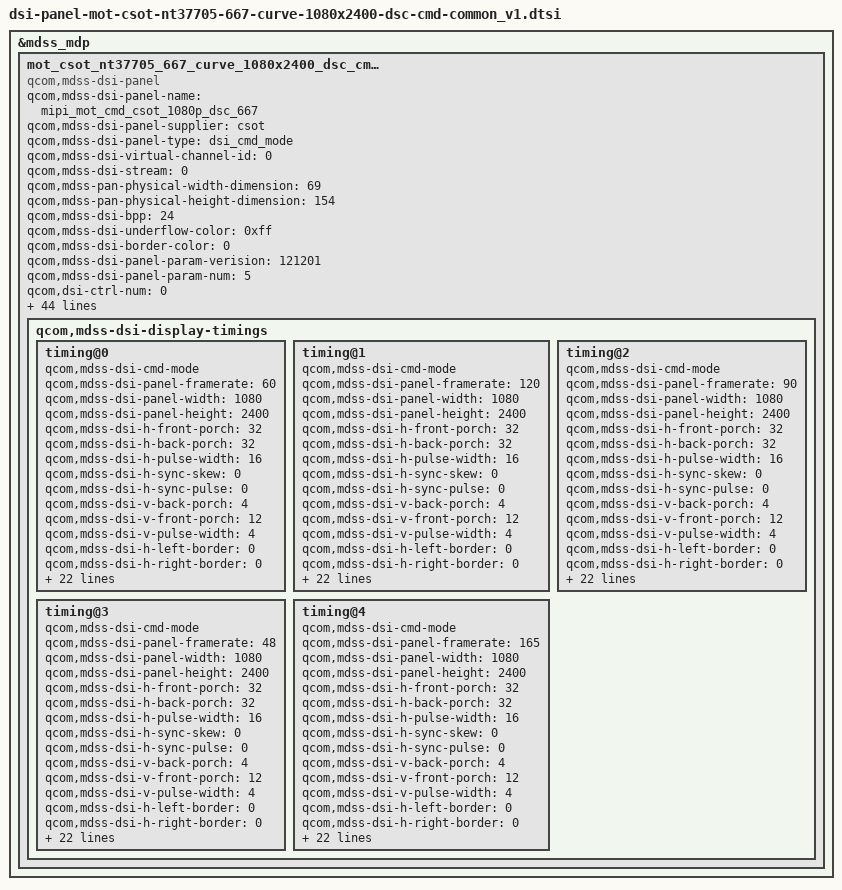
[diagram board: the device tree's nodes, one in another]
/* Copyright (c) 2019-2020, The Linux Foundation. All rights reserved.
 *
 * This program is free software; you can redistribute it and/or modify
 * it under the terms of the GNU General Public License version 2 and
 * only version 2 as published by the Free Software Foundation.
 *
 * This program is distributed in the hope that it will be useful,
 * but WITHOUT ANY WARRANTY; without even the implied warranty of
 * MERCHANTABILITY or FITNESS FOR A PARTICULAR PURPOSE.  See the
 * GNU General Public License for more details.
 */
#include "dsi-panel-mot-csot-nt37705-667-curve-1080x2400-dsc-cmd-common_v1_lhbm.dtsi"
&mdss_mdp {
mot_csot_nt37705_667_curve_1080x2400_dsc_cmd_v1: qcom,mdss_dsi_mot_csot_nt37705_667_curve_1080x2400_dsc_cmd_v1 {
compatible = "qcom,mdss-dsi-panel";
qcom,mdss-dsi-panel-name = "mipi_mot_cmd_csot_1080p_dsc_667";
qcom,mdss-dsi-panel-supplier = "csot";
qcom,mdss-dsi-panel-type = "dsi_cmd_mode";
qcom,mdss-dsi-virtual-channel-id = <0>;
qcom,mdss-dsi-stream = <0>;
qcom,mdss-pan-physical-width-dimension = <69>;
qcom,mdss-pan-physical-height-dimension = <154>;
qcom,mdss-dsi-bpp = <24>;
qcom,mdss-dsi-underflow-color = <0xff>;
qcom,mdss-dsi-border-color = <0>;
qcom,mdss-dsi-panel-param-verision = <121201>;
qcom,mdss-dsi-panel-param-num = <5>;

qcom,dsi-ctrl-num = <0>;
qcom,dsi-phy-num = <0>;

qcom,mdss-dsi-traffic-mode = "burst_mode";
qcom,mdss-dsi-bllp-eof-power-mode;
qcom,mdss-dsi-bllp-power-mode;
qcom,mdss-dsi-lane-0-state;
qcom,mdss-dsi-lane-1-state;
qcom,mdss-dsi-lane-2-state;
qcom,mdss-dsi-lane-3-state;

qcom,mdss-dsi-dma-trigger = "trigger_sw";
qcom,mdss-dsi-mdp-trigger = "none";
qcom,mdss-dsi-reset-sequence = <0 12>, <1 1>, <0 1>, <1 13>;
qcom,mdss-dsi-lp11-init;
qcom,mdss-dsi-tx-eot-append;
qcom,mdss-dsi-te-pin-select = <1>;
qcom,mdss-dsi-te-dcs-command = <1>;
qcom,mdss-dsi-te-using-te-pin;

//qcom,bklt-dcs-2bytes-enabled;
qcom,mdss-dsi-bl-min-level = <4>;
qcom,mdss-dsi-bl-max-level = <14056>;
qcom,mdss-dsi-bl-pmic-control-type = "bl_ctrl_dcs";

qcom,mdss-dsi-panel-hdr-enabled;
qcom,mdss-dsi-panel-hdr-color-primaries = <14500 15500 32000
	        17000 15500 30000 8000 3000>;
qcom,mdss-dsi-panel-peak-brightness = <4200000>;

qcom,mdss-dsi-panel-blackness-level = <3230>;

qcom,mdss-dsi-dc-on-command = [
		39 00 00 00 00 00 06 F0 55 AA 52 08 00
		39 00 00 40 00 00 02 B2 81
		39 00 00 40 00 00 02 6F 02
		39 00 00 40 00 00 02 B2 3F
		39 00 00 40 00 00 02 6F 11
		39 00 00 00 00 00 04 B2 00 00 00
		39 00 00 40 00 00 1F B3 00 00 00 00 00 00 00 00 00 00 00 00 00 00 00 00 00 00 00 00 00 00 00 00 00 00 00 00 06 8F
		39 00 00 40 00 00 02 6F 1E
		39 00 00 00 00 00 0F B3 06 90 06 90 09 08 09 08 0D BA 0D BA 0F FF
		39 00 00 40 00 00 06 F0 55 AA 52 08 00
		39 00 00 40 00 00 02 6F 2E
		39 00 00 40 00 00 04 C0 08 9A BC
		39 00 00 40 00 00 06 F0 55 AA 52 08 02
		39 00 00 00 00 00 02 CC 10
		];

qcom,mdss-dsi-dc-on-command-state = "dsi_hs_mode";
qcom,mdss-dsi-dc-off-command = [
		39 00 00 00 00 00 06 F0 55 AA 52 08 00
		39 00 00 40 00 00 02 B2 01
		39 00 00 40 00 00 1F B3 00 01 01 59 01 59 02 1A 02 1A 03 0A 03 0A 04 44 04 44 05 8E 05 8E 06 8A 06 8A 06 8F 06 8F
		39 00 00 40 00 00 02 6F 1E
		39 00 00 00 00 00 0F B3 06 90 06 90 09 08 09 08 0D BA 0D BA 0F FF
		39 00 00 40 00 00 06 F0 55 AA 52 08 00
                39 00 00 40 00 00 02 6F 11
		39 00 00 00 00 00 04 B2 0B 05 44
		39 00 00 40 00 00 02 6F 2E
		39 00 00 00 00 00 04 C0 12 34 56
		39 00 00 40 00 00 06 F0 55 AA 52 08 02
		39 00 00 00 00 00 02 CC 10
		];
qcom,mdss-dsi-dc-off-command-state = "dsi_hs_mode";

qcom,mdss-dsi-hbm-on-command = [
		39 00 00 00 00 00 03 51 3F FC
		39 00 00 00 00 00 02 87 00];

qcom,mdss-dsi-hbm-off-command = [
		39 00 00 00 00 00 02 87 00];

qcom,mdss-dsi-hbm-fod;
qcom,mdss-dsi-hbm-fod-on-command = [
		39 00 00 40 00 00 06 F0 55 AA 52 08 00
		39 00 00 40 00 00 0A 88 01 02 1C 08 5E 00 00 00 00
		39 00 00 40 00 00 02 6F 4C
		39 00 00 40 00 00 03 DF 3F FF
		39 00 00 40 00 00 02 6F 01
		39 00 00 40 00 00 03 87 0F FF
		39 00 00 00 00 00 02 87 25];

qcom,mdss-dsi-panel-local-hbm-enabled;
qcom,mdss-dsi-panel-local-hbm-alpha-register = <0x87>;
qcom,mdss-dsi-panel-local-hbm-alpha-size = <4096>;

qcom,mdss-dsi-display-timings {
	timing@0{
		qcom,mdss-dsi-cmd-mode;
		qcom,mdss-dsi-panel-framerate = <60>;
		qcom,mdss-dsi-panel-width = <1080>;
		qcom,mdss-dsi-panel-height = <2400>;
		qcom,mdss-dsi-h-front-porch = <32>;
		qcom,mdss-dsi-h-back-porch = <32>;
		qcom,mdss-dsi-h-pulse-width = <16>;
		qcom,mdss-dsi-h-sync-skew = <0>;
		qcom,mdss-dsi-h-sync-pulse = <0>;
		qcom,mdss-dsi-v-back-porch = <4>;
		qcom,mdss-dsi-v-front-porch = <12>;
		qcom,mdss-dsi-v-pulse-width = <4>;
		qcom,mdss-dsi-h-left-border = <0>;
		qcom,mdss-dsi-h-right-border = <0>;
		qcom,mdss-dsi-v-top-border = <0>;
		qcom,mdss-dsi-v-bottom-border = <0>;
		qcom,mdss-mdp-transfer-time-us = <5500>;
		qcom,mdss-dsi-timing-switch-command = [
			15 01 00 00 10 00 02 2F 01 //05:48Hz 01:60Hz 04:90Hz 02:120Hz 03:165HZ
			39 01 00 40 00 00 06 F0 55 AA 52 08 08
			39 01 00 00 00 00 02 E0 00
		];
		qcom,mdss-dsi-on-command = [
			39 01 00 00 00 00 06 F0 55 AA 52 08 00
			39 01 00 00 00 00 08 BA 00 6A 00 10 09 B0 10
			39 01 00 00 00 00 02 6F 07
			39 01 00 00 00 00 08 BA 00 6A 00 10 00 20 10
			39 01 00 00 00 00 02 6F 0E
			39 01 00 00 00 00 08 BA 00 4C 00 10 00 2C 10
			39 01 00 00 00 00 08 BB 00 6A 00 10 00 20 70
			39 01 00 00 00 00 0B C1 00 6A 00 6A 00 4C 00 6A 00 6A
			39 01 00 00 00 00 06 F0 55 AA 52 08 08
			39 01 00 00 00 00 06 E0 41 73 73 73 83
			39 01 00 00 00 00 16 E1 00 5C C4 E8 00 00 00 00 00 00 00 00 00 00 00 00 00 00 E8 10 00
			39 01 00 00 00 00 16 E2 41 8D 73 00 00 00 00 00 00 00 00 00 00 00 00 00 00 00 7C 00 00
			39 01 00 00 00 00 16 E3 00 00 00 00 00 00 00 00 00 00 00 00 00 00 00 00 00 00 00 00 00
			39 01 00 00 00 00 13 E4 00 00 00 00 00 00 00 00 00 00 00 00 00 00 00 00 00 00
			39 01 00 00 00 00 13 E5 00 00 00 00 00 00 00 00 00 00 00 00 00 00 00 00 00 00
			39 01 00 00 00 00 13 E6 00 00 00 00 00 00 00 00 00 00 00 00 00 00 00 00 00 00
			39 01 00 00 00 00 06 F0 55 AA 52 08 07
			39 01 00 00 00 00 02 6F 37
			39 01 00 00 00 00 04 B7 08 08 08
			39 01 00 00 00 00 06 F0 55 AA 52 08 00
			39 01 00 00 00 00 02 6F 01
			39 01 00 00 00 00 02 C0 20
			39 01 00 00 00 00 06 F0 55 AA 52 08 08
			39 01 00 00 00 00 22 EA 22 00 00 02 00 00 00 00 00 00 00 00 00 00 00 00 00 00 00 00 00 00 00 00 00 00 00 00 00 00 00 00 00
			39 01 00 00 00 00 06 F0 55 AA 52 08 08
			39 01 00 00 00 00 02 6F 21
			39 01 00 00 00 00 07 EA 00 00 00 00 00 00
			39 01 00 00 00 00 05 FF AA 55 A5 83
			39 01 00 00 00 00 02 6F 02
			39 01 00 00 00 00 02 FE 03
			39 01 00 00 00 00 06 F0 55 AA 52 08 08
			39 01 00 00 00 00 02 E0 00
                        39 01 00 00 00 00 05 FF AA 55 A5 81
                        39 01 00 00 00 00 02 6F 1E
                        39 01 00 00 00 00 02 FB 0F
                        39 01 00 00 00 00 06 F0 55 AA 52 08 01
                        39 01 00 00 00 00 02 6F 05
                        39 01 00 00 00 00 04 C5 15 15 15
                        39 01 00 00 00 00 05 FF AA 55 A5 81
                        39 01 00 00 00 00 02 6F 19
                        39 01 00 00 00 00 02 FB 00
                        39 01 00 00 00 00 05 FF AA 55 A5 80
                        39 01 00 00 00 00 02 6F 2D
                        39 01 00 00 00 00 02 FC 44
                        39 01 00 00 00 00 05 FF AA 55 A5 80
                        39 01 00 00 00 00 02 6F 1A
                        39 01 00 00 00 00 02 F4 55
                        39 01 00 00 00 00 05 FF AA 55 A5 83
                        39 01 00 00 00 00 02 6F 12
                        39 01 00 00 00 00 02 FE 41
                        39 01 00 00 00 00 05 FF AA 55 A5 80
                        39 01 00 00 00 00 02 6F 18
                        39 01 00 00 00 00 02 F4 30
                        39 01 00 00 00 00 05 FF AA 55 A5 80
                        39 01 00 00 00 00 02 6F 19
                        39 01 00 00 00 00 02 F2 00
                        39 01 00 00 00 00 05 FF AA 55 A5 80
                        39 01 00 00 00 00 02 6F 31
                        39 01 00 00 00 00 03 F8 01 09
                        39 01 00 00 00 00 02 6F 15
                        39 01 00 00 00 00 03 F8 01 5E
                        39 01 00 00 00 00 02 17 10
                        39 01 00 00 00 00 05 2A 00 00 04 37
                        39 01 00 00 00 00 05 2B 00 00 09 5F
                        39 01 00 00 00 00 02 2F 01
                        39 01 00 00 00 00 02 5F 80
                        39 01 00 00 00 00 02 35 00
                        39 01 00 00 00 00 03 51 00 00
                        39 01 00 00 00 00 02 6F 04
                        39 01 00 00 00 00 03 51 00 00
                        39 01 00 00 00 00 02 53 20
                        39 01 00 00 00 00 03 90 03 03
                        39 01 00 00 00 00 13 91 AB 28 00 0C D2 00 02 25 01 14 00 07 09 75 08 7A 10 F0
                        39 01 00 00 00 00 06 F0 55 AA 52 08 01
                        39 01 00 00 00 00 02 6F 02
                        39 01 00 00 00 00 03 C7 00 00
                        39 01 00 00 00 00 02 26 00
                        39 01 00 00 00 00 02 1F 40
                        39 01 00 00 00 00 06 F0 55 AA 52 08 00
                        39 01 00 00 00 00 03 B2 01 60
			05 01 00 00 64 00 01 11
                        05 01 00 00 00 00 01 29];	/* display on */
		qcom,mdss-dsi-off-command = [
			05 01 00 00 00 00 01 28		/* display_off */
			05 01 00 00 78 00 01 10];	/* enter sleep mode */

		qcom,mdss-dsi-on-command-state = "dsi_lp_mode";
		qcom,mdss-dsi-off-command-state = "dsi_lp_mode";
		qcom,mdss-dsi-timing-switch-command-state =
			"dsi_lp_mode";
		qcom,compression-mode = "dsc";
		/* Why QCOM doesn't use this, even it used 2 encoder
		 * as for that dsi_sw43404_amoled_cmd, for ex */
		/* qcom,mdss-dsc-encoders = <2>; */
		qcom,mdss-dsc-version = <0x11>;
		qcom,mdss-dsc-slice-height = <12>;
		qcom,mdss-dsc-slice-width = <540>;
		qcom,mdss-dsc-slice-per-pkt = <1>;
		qcom,mdss-dsc-bit-per-component = <10>;
		qcom,mdss-dsc-bit-per-pixel = <8>;
		qcom,mdss-dsc-block-prediction-enable;
		qcom,mdss-dsc-novateck-ic;
	};

	timing@1{
		qcom,mdss-dsi-cmd-mode;
		qcom,mdss-dsi-panel-framerate = <120>;
		qcom,mdss-dsi-panel-width = <1080>;
		qcom,mdss-dsi-panel-height = <2400>;
		qcom,mdss-dsi-h-front-porch = <32>;
		qcom,mdss-dsi-h-back-porch = <32>;
		qcom,mdss-dsi-h-pulse-width = <16>;
		qcom,mdss-dsi-h-sync-skew = <0>;
		qcom,mdss-dsi-h-sync-pulse = <0>;
		qcom,mdss-dsi-v-back-porch = <4>;
		qcom,mdss-dsi-v-front-porch = <12>;
		qcom,mdss-dsi-v-pulse-width = <4>;
		qcom,mdss-dsi-h-left-border = <0>;
		qcom,mdss-dsi-h-right-border = <0>;
		qcom,mdss-dsi-v-top-border = <0>;
		qcom,mdss-dsi-v-bottom-border = <0>;
		qcom,mdss-mdp-transfer-time-us = <5500>;
		qcom,mdss-dsi-timing-switch-command = [
			15 01 00 00 10 00 02 2F 02 //05:48Hz 01:60Hz 04:90Hz 02:120Hz 03:165HZ
			39 01 00 40 00 00 06 F0 55 AA 52 08 08
			39 01 00 00 00 00 02 E0 41
		];
		qcom,mdss-dsi-on-command = [
			39 01 00 00 00 00 06 F0 55 AA 52 08 00
			39 01 00 00 00 00 08 BA 00 6A 00 10 09 B0 10
			39 01 00 00 00 00 02 6F 07
			39 01 00 00 00 00 08 BA 00 6A 00 10 00 20 10
			39 01 00 00 00 00 02 6F 0E
			39 01 00 00 00 00 08 BA 00 4C 00 10 00 2C 10
			39 01 00 00 00 00 08 BB 00 6A 00 10 00 20 70
			39 01 00 00 00 00 0B C1 00 6A 00 6A 00 4C 00 6A 00 6A
                        39 01 00 00 00 00 06 F0 55 AA 52 08 08
			39 01 00 00 00 00 06 E0 41 73 73 73 83
			39 01 00 00 00 00 16 E1 00 5C C4 E8 00 00 00 00 00 00 00 00 00 00 00 00 00 00 E8 10 00
			39 01 00 00 00 00 16 E2 41 8D 73 00 00 00 00 00 00 00 00 00 00 00 00 00 00 00 7C 00 00
			39 01 00 00 00 00 16 E3 00 00 00 00 00 00 00 00 00 00 00 00 00 00 00 00 00 00 00 00 00
			39 01 00 00 00 00 13 E4 00 00 00 00 00 00 00 00 00 00 00 00 00 00 00 00 00 00
			39 01 00 00 00 00 13 E5 00 00 00 00 00 00 00 00 00 00 00 00 00 00 00 00 00 00
			39 01 00 00 00 00 13 E6 00 00 00 00 00 00 00 00 00 00 00 00 00 00 00 00 00 00
			39 01 00 00 00 00 06 F0 55 AA 52 08 07
			39 01 00 00 00 00 02 6F 37
			39 01 00 00 00 00 04 B7 08 08 08
			39 01 00 00 00 00 06 F0 55 AA 52 08 00
			39 01 00 00 00 00 02 6F 01
			39 01 00 00 00 00 02 C0 20
			39 01 00 00 00 00 06 F0 55 AA 52 08 08
			39 01 00 00 00 00 22 EA 22 00 00 02 00 00 00 00 00 00 00 00 00 00 00 00 00 00 00 00 00 00 00 00 00 00 00 00 00 00 00 00 00
			39 01 00 00 00 00 06 F0 55 AA 52 08 08
			39 01 00 00 00 00 02 6F 21
			39 01 00 00 00 00 07 EA 00 00 00 00 00 00
			39 01 00 00 00 00 05 FF AA 55 A5 83
			39 01 00 00 00 00 02 6F 02
			39 01 00 00 00 00 02 FE 03
			39 01 00 00 00 00 06 F0 55 AA 52 08 08
			39 01 00 00 00 00 02 E0 41
                        39 01 00 00 00 00 05 FF AA 55 A5 81
                        39 01 00 00 00 00 02 6F 1E
                        39 01 00 00 00 00 02 FB 0F
                        39 01 00 00 00 00 06 F0 55 AA 52 08 01
                        39 01 00 00 00 00 02 6F 05
                        39 01 00 00 00 00 04 C5 15 15 15
                        39 01 00 00 00 00 05 FF AA 55 A5 81
                        39 01 00 00 00 00 02 6F 19
                        39 01 00 00 00 00 02 FB 00
                        39 01 00 00 00 00 05 FF AA 55 A5 80
                        39 01 00 00 00 00 02 6F 2D
                        39 01 00 00 00 00 02 FC 44
                        39 01 00 00 00 00 05 FF AA 55 A5 80
                        39 01 00 00 00 00 02 6F 1A
                        39 01 00 00 00 00 02 F4 55
                        39 01 00 00 00 00 05 FF AA 55 A5 83
                        39 01 00 00 00 00 02 6F 12
                        39 01 00 00 00 00 02 FE 41
                        39 01 00 00 00 00 05 FF AA 55 A5 80
                        39 01 00 00 00 00 02 6F 18
                        39 01 00 00 00 00 02 F4 30
                        39 01 00 00 00 00 05 FF AA 55 A5 80
                        39 01 00 00 00 00 02 6F 19
                        39 01 00 00 00 00 02 F2 00
                        39 01 00 00 00 00 05 FF AA 55 A5 80
                        39 01 00 00 00 00 02 6F 31
                        39 01 00 00 00 00 03 F8 01 09
                        39 01 00 00 00 00 02 6F 15
                        39 01 00 00 00 00 03 F8 01 5E
                        39 01 00 00 00 00 02 17 10
                        39 01 00 00 00 00 05 2A 00 00 04 37
                        39 01 00 00 00 00 05 2B 00 00 09 5F
                        39 01 00 00 00 00 02 2F 02
                        39 01 00 00 00 00 02 5F 80
                        39 01 00 00 00 00 02 35 00
                        39 01 00 00 00 00 03 51 00 00
                        39 01 00 00 00 00 02 6F 04
                        39 01 00 00 00 00 03 51 00 00
                        39 01 00 00 00 00 02 53 20
                        39 01 00 00 00 00 03 90 03 03
                        39 01 00 00 00 00 13 91 AB 28 00 0C D2 00 02 25 01 14 00 07 09 75 08 7A 10 F0
                        39 01 00 00 00 00 06 F0 55 AA 52 08 01
                        39 01 00 00 00 00 02 6F 02
                        39 01 00 00 00 00 03 C7 00 00
                        39 01 00 00 00 00 02 26 00
                        39 01 00 00 00 00 02 1F 40
                        39 01 00 00 00 00 06 F0 55 AA 52 08 00
                        39 01 00 00 00 00 03 B2 01 60
			05 01 00 00 64 00 01 11
                        05 01 00 00 00 00 01 29];	/* display on */
		qcom,mdss-dsi-off-command = [
			05 01 00 00 00 00 01 28		/* display_off */
			05 01 00 00 78 00 01 10];	/* enter sleep mode */

		qcom,mdss-dsi-on-command-state = "dsi_lp_mode";
		qcom,mdss-dsi-off-command-state = "dsi_lp_mode";
		qcom,mdss-dsi-timing-switch-command-state =
			"dsi_lp_mode";
		qcom,compression-mode = "dsc";
		/* Why QCOM doesn't use this, even it used 2 encoder
		 * as for that dsi_sw43404_amoled_cmd, for ex */
		/* qcom,mdss-dsc-encoders = <2>; */
		qcom,mdss-dsc-version = <0x11>;
		qcom,mdss-dsc-slice-height = <12>;
		qcom,mdss-dsc-slice-width = <540>;
		qcom,mdss-dsc-slice-per-pkt = <1>;
		qcom,mdss-dsc-bit-per-component = <10>;
		qcom,mdss-dsc-bit-per-pixel = <8>;
		qcom,mdss-dsc-block-prediction-enable;
		qcom,mdss-dsc-novateck-ic;
	};
	timing@2{
		qcom,mdss-dsi-cmd-mode;
		qcom,mdss-dsi-panel-framerate = <90>;
		qcom,mdss-dsi-panel-width = <1080>;
		qcom,mdss-dsi-panel-height = <2400>;
		qcom,mdss-dsi-h-front-porch = <32>;
		qcom,mdss-dsi-h-back-porch = <32>;
		qcom,mdss-dsi-h-pulse-width = <16>;
		qcom,mdss-dsi-h-sync-skew = <0>;
		qcom,mdss-dsi-h-sync-pulse = <0>;
		qcom,mdss-dsi-v-back-porch = <4>;
		qcom,mdss-dsi-v-front-porch = <12>;
		qcom,mdss-dsi-v-pulse-width = <4>;
		qcom,mdss-dsi-h-left-border = <0>;
		qcom,mdss-dsi-h-right-border = <0>;
		qcom,mdss-dsi-v-top-border = <0>;
		qcom,mdss-dsi-v-bottom-border = <0>;
		qcom,mdss-mdp-transfer-time-us = <5500>;
		qcom,mdss-dsi-timing-switch-command = [
			15 01 00 00 10 00 02 2F 04 //05:48Hz 01:60Hz 04:90Hz 02:120Hz 03:165HZ
			39 01 00 40 00 00 06 F0 55 AA 52 08 08
			39 01 00 00 00 00 02 E0 00
		];
		qcom,mdss-dsi-on-command = [
			39 01 00 00 00 00 06 F0 55 AA 52 08 00
			39 01 00 00 00 00 08 BA 00 6A 00 10 09 B0 10
			39 01 00 00 00 00 02 6F 07
			39 01 00 00 00 00 08 BA 00 6A 00 10 00 20 10
			39 01 00 00 00 00 02 6F 0E
			39 01 00 00 00 00 08 BA 00 4C 00 10 00 2C 10
			39 01 00 00 00 00 08 BB 00 6A 00 10 00 20 70
			39 01 00 00 00 00 0B C1 00 6A 00 6A 00 4C 00 6A 00 6A
                        39 01 00 00 00 00 06 F0 55 AA 52 08 08
			39 01 00 00 00 00 06 E0 41 73 73 73 83
			39 01 00 00 00 00 16 E1 00 5C C4 E8 00 00 00 00 00 00 00 00 00 00 00 00 00 00 E8 10 00
			39 01 00 00 00 00 16 E2 41 8D 73 00 00 00 00 00 00 00 00 00 00 00 00 00 00 00 7C 00 00
			39 01 00 00 00 00 16 E3 00 00 00 00 00 00 00 00 00 00 00 00 00 00 00 00 00 00 00 00 00
			39 01 00 00 00 00 13 E4 00 00 00 00 00 00 00 00 00 00 00 00 00 00 00 00 00 00
			39 01 00 00 00 00 13 E5 00 00 00 00 00 00 00 00 00 00 00 00 00 00 00 00 00 00
			39 01 00 00 00 00 13 E6 00 00 00 00 00 00 00 00 00 00 00 00 00 00 00 00 00 00
			39 01 00 00 00 00 06 F0 55 AA 52 08 07
			39 01 00 00 00 00 02 6F 37
			39 01 00 00 00 00 04 B7 08 08 08
			39 01 00 00 00 00 06 F0 55 AA 52 08 00
			39 01 00 00 00 00 02 6F 01
			39 01 00 00 00 00 02 C0 20
			39 01 00 00 00 00 06 F0 55 AA 52 08 08
			39 01 00 00 00 00 22 EA 22 00 00 02 00 00 00 00 00 00 00 00 00 00 00 00 00 00 00 00 00 00 00 00 00 00 00 00 00 00 00 00 00
			39 01 00 00 00 00 06 F0 55 AA 52 08 08
			39 01 00 00 00 00 02 6F 21
			39 01 00 00 00 00 07 EA 00 00 00 00 00 00
			39 01 00 00 00 00 05 FF AA 55 A5 83
			39 01 00 00 00 00 02 6F 02
			39 01 00 00 00 00 02 FE 03
			39 01 00 00 00 00 06 F0 55 AA 52 08 08
			39 01 00 00 00 00 02 E0 00
                        39 01 00 00 00 00 05 FF AA 55 A5 81
                        39 01 00 00 00 00 02 6F 1E
                        39 01 00 00 00 00 02 FB 0F
                        39 01 00 00 00 00 06 F0 55 AA 52 08 01
                        39 01 00 00 00 00 02 6F 05
                        39 01 00 00 00 00 04 C5 15 15 15
                        39 01 00 00 00 00 05 FF AA 55 A5 81
                        39 01 00 00 00 00 02 6F 19
                        39 01 00 00 00 00 02 FB 00
                        39 01 00 00 00 00 05 FF AA 55 A5 80
                        39 01 00 00 00 00 02 6F 2D
                        39 01 00 00 00 00 02 FC 44
                        39 01 00 00 00 00 05 FF AA 55 A5 80
                        39 01 00 00 00 00 02 6F 1A
                        39 01 00 00 00 00 02 F4 55
                        39 01 00 00 00 00 05 FF AA 55 A5 83
                        39 01 00 00 00 00 02 6F 12
                        39 01 00 00 00 00 02 FE 41
                        39 01 00 00 00 00 05 FF AA 55 A5 80
                        39 01 00 00 00 00 02 6F 18
                        39 01 00 00 00 00 02 F4 30
                        39 01 00 00 00 00 05 FF AA 55 A5 80
                        39 01 00 00 00 00 02 6F 19
                        39 01 00 00 00 00 02 F2 00
                        39 01 00 00 00 00 05 FF AA 55 A5 80
                        39 01 00 00 00 00 02 6F 31
                        39 01 00 00 00 00 03 F8 01 09
                        39 01 00 00 00 00 02 6F 15
                        39 01 00 00 00 00 03 F8 01 5E
                        39 01 00 00 00 00 02 17 10
                        39 01 00 00 00 00 05 2A 00 00 04 37
                        39 01 00 00 00 00 05 2B 00 00 09 5F
                        39 01 00 00 00 00 02 2F 04
                        39 01 00 00 00 00 02 5F 80
                        39 01 00 00 00 00 02 35 00
                        39 01 00 00 00 00 03 51 00 00
                        39 01 00 00 00 00 02 6F 04
                        39 01 00 00 00 00 03 51 00 00
                        39 01 00 00 00 00 02 53 20
                        39 01 00 00 00 00 03 90 03 03
                        39 01 00 00 00 00 13 91 AB 28 00 0C D2 00 02 25 01 14 00 07 09 75 08 7A 10 F0
                        39 01 00 00 00 00 06 F0 55 AA 52 08 01
                        39 01 00 00 00 00 02 6F 02
                        39 01 00 00 00 00 03 C7 00 00
                        39 01 00 00 00 00 02 26 00
                        39 01 00 00 00 00 02 1F 40
                        39 01 00 00 00 00 06 F0 55 AA 52 08 00
                        39 01 00 00 00 00 03 B2 01 60
			05 01 00 00 64 00 01 11
                        05 01 00 00 00 00 01 29];	/* display on */
		qcom,mdss-dsi-off-command = [
			05 01 00 00 00 00 01 28		/* display_off */
			05 01 00 00 78 00 01 10];	/* enter sleep mode */

		qcom,mdss-dsi-on-command-state = "dsi_lp_mode";
		qcom,mdss-dsi-off-command-state = "dsi_lp_mode";
		qcom,mdss-dsi-timing-switch-command-state =
			"dsi_lp_mode";
		qcom,compression-mode = "dsc";
		/* Why QCOM doesn't use this, even it used 2 encoder
		 * as for that dsi_sw43404_amoled_cmd, for ex */
		/* qcom,mdss-dsc-encoders = <2>; */
		qcom,mdss-dsc-version = <0x11>;
		qcom,mdss-dsc-slice-height = <12>;
		qcom,mdss-dsc-slice-width = <540>;
		qcom,mdss-dsc-slice-per-pkt = <1>;
		qcom,mdss-dsc-bit-per-component = <10>;
		qcom,mdss-dsc-bit-per-pixel = <8>;
		qcom,mdss-dsc-block-prediction-enable;
		qcom,mdss-dsc-novateck-ic;
	};
	timing@3{
		qcom,mdss-dsi-cmd-mode;
		qcom,mdss-dsi-panel-framerate = <48>;
		qcom,mdss-dsi-panel-width = <1080>;
		qcom,mdss-dsi-panel-height = <2400>;
		qcom,mdss-dsi-h-front-porch = <32>;
		qcom,mdss-dsi-h-back-porch = <32>;
		qcom,mdss-dsi-h-pulse-width = <16>;
		qcom,mdss-dsi-h-sync-skew = <0>;
		qcom,mdss-dsi-h-sync-pulse = <0>;
		qcom,mdss-dsi-v-back-porch = <4>;
		qcom,mdss-dsi-v-front-porch = <12>;
		qcom,mdss-dsi-v-pulse-width = <4>;
		qcom,mdss-dsi-h-left-border = <0>;
		qcom,mdss-dsi-h-right-border = <0>;
		qcom,mdss-dsi-v-top-border = <0>;
		qcom,mdss-dsi-v-bottom-border = <0>;
		qcom,mdss-mdp-transfer-time-us = <5500>;
		qcom,mdss-dsi-timing-switch-command = [
			15 01 00 00 10 00 02 2F 05 //05:48Hz 01:60Hz 04:90Hz 02:120Hz 03:165HZ
			39 01 00 40 00 00 06 F0 55 AA 52 08 08
			39 01 00 00 00 00 02 E0 00
		];
		qcom,mdss-dsi-on-command = [
			39 01 00 00 00 00 06 F0 55 AA 52 08 00
			39 01 00 00 00 00 08 BA 00 6A 00 10 09 B0 10
			39 01 00 00 00 00 02 6F 07
			39 01 00 00 00 00 08 BA 00 6A 00 10 00 20 10
			39 01 00 00 00 00 02 6F 0E
			39 01 00 00 00 00 08 BA 00 4C 00 10 00 2C 10
			39 01 00 00 00 00 08 BB 00 6A 00 10 00 20 70
			39 01 00 00 00 00 0B C1 00 6A 00 6A 00 4C 00 6A 00 6A
			39 01 00 00 00 00 06 F0 55 AA 52 08 08
			39 01 00 00 00 00 06 E0 41 73 73 73 83
			39 01 00 00 00 00 16 E1 00 5C C4 E8 00 00 00 00 00 00 00 00 00 00 00 00 00 00 E8 10 00
			39 01 00 00 00 00 16 E2 41 8D 73 00 00 00 00 00 00 00 00 00 00 00 00 00 00 00 7C 00 00
			39 01 00 00 00 00 16 E3 00 00 00 00 00 00 00 00 00 00 00 00 00 00 00 00 00 00 00 00 00
			39 01 00 00 00 00 13 E4 00 00 00 00 00 00 00 00 00 00 00 00 00 00 00 00 00 00
			39 01 00 00 00 00 13 E5 00 00 00 00 00 00 00 00 00 00 00 00 00 00 00 00 00 00
			39 01 00 00 00 00 13 E6 00 00 00 00 00 00 00 00 00 00 00 00 00 00 00 00 00 00
			39 01 00 00 00 00 06 F0 55 AA 52 08 07
			39 01 00 00 00 00 02 6F 37
			39 01 00 00 00 00 04 B7 08 08 08
			39 01 00 00 00 00 06 F0 55 AA 52 08 00
			39 01 00 00 00 00 02 6F 01
			39 01 00 00 00 00 02 C0 20
			39 01 00 00 00 00 06 F0 55 AA 52 08 08
			39 01 00 00 00 00 22 EA 22 00 00 02 00 00 00 00 00 00 00 00 00 00 00 00 00 00 00 00 00 00 00 00 00 00 00 00 00 00 00 00 00
			39 01 00 00 00 00 06 F0 55 AA 52 08 08
			39 01 00 00 00 00 02 6F 21
			39 01 00 00 00 00 07 EA 00 00 00 00 00 00
			39 01 00 00 00 00 05 FF AA 55 A5 83
			39 01 00 00 00 00 02 6F 02
			39 01 00 00 00 00 02 FE 03
			39 01 00 00 00 00 06 F0 55 AA 52 08 08
			39 01 00 00 00 00 02 E0 00
                        39 01 00 00 00 00 05 FF AA 55 A5 81
                        39 01 00 00 00 00 02 6F 1E
                        39 01 00 00 00 00 02 FB 0F
                        39 01 00 00 00 00 06 F0 55 AA 52 08 01
                        39 01 00 00 00 00 02 6F 05
                        39 01 00 00 00 00 04 C5 15 15 15
                        39 01 00 00 00 00 05 FF AA 55 A5 81
                        39 01 00 00 00 00 02 6F 19
                        39 01 00 00 00 00 02 FB 00
                        39 01 00 00 00 00 05 FF AA 55 A5 80
                        39 01 00 00 00 00 02 6F 2D
                        39 01 00 00 00 00 02 FC 44
                        39 01 00 00 00 00 05 FF AA 55 A5 80
                        39 01 00 00 00 00 02 6F 1A
                        39 01 00 00 00 00 02 F4 55
                        39 01 00 00 00 00 05 FF AA 55 A5 83
                        39 01 00 00 00 00 02 6F 12
                        39 01 00 00 00 00 02 FE 41
                        39 01 00 00 00 00 05 FF AA 55 A5 80
                        39 01 00 00 00 00 02 6F 18
                        39 01 00 00 00 00 02 F4 30
                        39 01 00 00 00 00 05 FF AA 55 A5 80
                        39 01 00 00 00 00 02 6F 19
                        39 01 00 00 00 00 02 F2 00
                        39 01 00 00 00 00 05 FF AA 55 A5 80
                        39 01 00 00 00 00 02 6F 31
                        39 01 00 00 00 00 03 F8 01 09
                        39 01 00 00 00 00 02 6F 15
                        39 01 00 00 00 00 03 F8 01 5E
                        39 01 00 00 00 00 02 17 10
                        39 01 00 00 00 00 05 2A 00 00 04 37
                        39 01 00 00 00 00 05 2B 00 00 09 5F
                        39 01 00 00 00 00 02 2F 05
                        39 01 00 00 00 00 02 5F 80
                        39 01 00 00 00 00 02 35 00
                        39 01 00 00 00 00 03 51 00 00
                        39 01 00 00 00 00 02 6F 04
                        39 01 00 00 00 00 03 51 00 00
                        39 01 00 00 00 00 02 53 20
                        39 01 00 00 00 00 03 90 03 03
                        39 01 00 00 00 00 13 91 AB 28 00 0C D2 00 02 25 01 14 00 07 09 75 08 7A 10 F0
                        39 01 00 00 00 00 06 F0 55 AA 52 08 01
                        39 01 00 00 00 00 02 6F 02
                        39 01 00 00 00 00 03 C7 00 00
                        39 01 00 00 00 00 02 26 00
                        39 01 00 00 00 00 02 1F 40
                        39 01 00 00 00 00 06 F0 55 AA 52 08 00
                        39 01 00 00 00 00 03 B2 01 60
			05 01 00 00 64 00 01 11
                        05 01 00 00 00 00 01 29];	/* display on */
		qcom,mdss-dsi-off-command = [
			05 01 00 00 00 00 01 28		/* display_off */
			05 01 00 00 78 00 01 10];	/* enter sleep mode */

		qcom,mdss-dsi-on-command-state = "dsi_lp_mode";
		qcom,mdss-dsi-off-command-state = "dsi_lp_mode";
		qcom,mdss-dsi-timing-switch-command-state =
			"dsi_lp_mode";
		qcom,compression-mode = "dsc";
		/* Why QCOM doesn't use this, even it used 2 encoder
		 * as for that dsi_sw43404_amoled_cmd, for ex */
		/* qcom,mdss-dsc-encoders = <2>; */
		qcom,mdss-dsc-version = <0x11>;
		qcom,mdss-dsc-slice-height = <12>;
		qcom,mdss-dsc-slice-width = <540>;
		qcom,mdss-dsc-slice-per-pkt = <1>;
		qcom,mdss-dsc-bit-per-component = <10>;
		qcom,mdss-dsc-bit-per-pixel = <8>;
		qcom,mdss-dsc-block-prediction-enable;
		qcom,mdss-dsc-novateck-ic;
	};
	timing@4{
		qcom,mdss-dsi-cmd-mode;
		qcom,mdss-dsi-panel-framerate = <165>;
		qcom,mdss-dsi-panel-width = <1080>;
		qcom,mdss-dsi-panel-height = <2400>;
		qcom,mdss-dsi-h-front-porch = <32>;
		qcom,mdss-dsi-h-back-porch = <32>;
		qcom,mdss-dsi-h-pulse-width = <16>;
		qcom,mdss-dsi-h-sync-skew = <0>;
		qcom,mdss-dsi-h-sync-pulse = <0>;
		qcom,mdss-dsi-v-back-porch = <4>;
		qcom,mdss-dsi-v-front-porch = <12>;
		qcom,mdss-dsi-v-pulse-width = <4>;
		qcom,mdss-dsi-h-left-border = <0>;
		qcom,mdss-dsi-h-right-border = <0>;
		qcom,mdss-dsi-v-top-border = <0>;
		qcom,mdss-dsi-v-bottom-border = <0>;
		qcom,mdss-mdp-transfer-time-us = <5500>;
		qcom,mdss-dsi-timing-switch-command = [
			15 01 00 00 10 00 02 2F 03 //05:48Hz 01:60Hz 04:90Hz 02:120Hz 03:165HZ
			39 01 00 40 00 00 06 F0 55 AA 52 08 08
			39 01 00 00 00 00 02 E0 41
		];
		qcom,mdss-dsi-on-command = [
			39 01 00 00 00 00 06 F0 55 AA 52 08 00
			39 01 00 00 00 00 08 BA 00 6A 00 10 09 B0 10
			39 01 00 00 00 00 02 6F 07
			39 01 00 00 00 00 08 BA 00 6A 00 10 00 20 10
			39 01 00 00 00 00 02 6F 0E
			39 01 00 00 00 00 08 BA 00 4C 00 10 00 2C 10
			39 01 00 00 00 00 08 BB 00 6A 00 10 00 20 70
			39 01 00 00 00 00 0B C1 00 6A 00 6A 00 4C 00 6A 00 6A
			39 01 00 00 00 00 06 F0 55 AA 52 08 08
			39 01 00 00 00 00 06 E0 41 73 73 73 83
			39 01 00 00 00 00 16 E1 00 5C C4 E8 00 00 00 00 00 00 00 00 00 00 00 00 00 00 E8 10 00
			39 01 00 00 00 00 16 E2 41 8D 73 00 00 00 00 00 00 00 00 00 00 00 00 00 00 00 7C 00 00
			39 01 00 00 00 00 16 E3 00 00 00 00 00 00 00 00 00 00 00 00 00 00 00 00 00 00 00 00 00
			39 01 00 00 00 00 13 E4 00 00 00 00 00 00 00 00 00 00 00 00 00 00 00 00 00 00
			39 01 00 00 00 00 13 E5 00 00 00 00 00 00 00 00 00 00 00 00 00 00 00 00 00 00
			39 01 00 00 00 00 13 E6 00 00 00 00 00 00 00 00 00 00 00 00 00 00 00 00 00 00
			39 01 00 00 00 00 06 F0 55 AA 52 08 07
			39 01 00 00 00 00 02 6F 37
			39 01 00 00 00 00 04 B7 08 08 08
			39 01 00 00 00 00 06 F0 55 AA 52 08 00
			39 01 00 00 00 00 02 6F 01
			39 01 00 00 00 00 02 C0 20
			39 01 00 00 00 00 06 F0 55 AA 52 08 08
			39 01 00 00 00 00 22 EA 22 00 00 02 00 00 00 00 00 00 00 00 00 00 00 00 00 00 00 00 00 00 00 00 00 00 00 00 00 00 00 00 00
			39 01 00 00 00 00 06 F0 55 AA 52 08 08
			39 01 00 00 00 00 02 6F 21
			39 01 00 00 00 00 07 EA 00 00 00 00 00 00
			39 01 00 00 00 00 05 FF AA 55 A5 83
			39 01 00 00 00 00 02 6F 02
			39 01 00 00 00 00 02 FE 03
			39 01 00 00 00 00 06 F0 55 AA 52 08 08
			39 01 00 00 00 00 02 E0 41
                        39 01 00 00 00 00 05 FF AA 55 A5 81
                        39 01 00 00 00 00 02 6F 1E
                        39 01 00 00 00 00 02 FB 0F
                        39 01 00 00 00 00 06 F0 55 AA 52 08 01
                        39 01 00 00 00 00 02 6F 05
                        39 01 00 00 00 00 04 C5 15 15 15
                        39 01 00 00 00 00 05 FF AA 55 A5 81
                        39 01 00 00 00 00 02 6F 19
                        39 01 00 00 00 00 02 FB 00
                        39 01 00 00 00 00 05 FF AA 55 A5 80
                        39 01 00 00 00 00 02 6F 2D
                        39 01 00 00 00 00 02 FC 44
                        39 01 00 00 00 00 05 FF AA 55 A5 80
                        39 01 00 00 00 00 02 6F 1A
                        39 01 00 00 00 00 02 F4 55
                        39 01 00 00 00 00 05 FF AA 55 A5 83
                        39 01 00 00 00 00 02 6F 12
                        39 01 00 00 00 00 02 FE 41
                        39 01 00 00 00 00 05 FF AA 55 A5 80
                        39 01 00 00 00 00 02 6F 18
                        39 01 00 00 00 00 02 F4 30
                        39 01 00 00 00 00 05 FF AA 55 A5 80
                        39 01 00 00 00 00 02 6F 19
                        39 01 00 00 00 00 02 F2 00
                        39 01 00 00 00 00 05 FF AA 55 A5 80
                        39 01 00 00 00 00 02 6F 31
                        39 01 00 00 00 00 03 F8 01 09
                        39 01 00 00 00 00 02 6F 15
                        39 01 00 00 00 00 03 F8 01 5E
                        39 01 00 00 00 00 02 17 10
                        39 01 00 00 00 00 05 2A 00 00 04 37
                        39 01 00 00 00 00 05 2B 00 00 09 5F
                        39 01 00 00 00 00 02 2F 03
                        39 01 00 00 00 00 02 5F 80
                        39 01 00 00 00 00 02 35 00
                        39 01 00 00 00 00 03 51 00 00
                        39 01 00 00 00 00 02 6F 04
                        39 01 00 00 00 00 03 51 00 00
                        39 01 00 00 00 00 02 53 20
                        39 01 00 00 00 00 03 90 03 03
                        39 01 00 00 00 00 13 91 AB 28 00 0C D2 00 02 25 01 14 00 07 09 75 08 7A 10 F0
                        39 01 00 00 00 00 06 F0 55 AA 52 08 01
                        39 01 00 00 00 00 02 6F 02
                        39 01 00 00 00 00 03 C7 00 00
                        39 01 00 00 00 00 02 26 00
                        39 01 00 00 00 00 02 1F 40
                        39 01 00 00 00 00 06 F0 55 AA 52 08 00
                        39 01 00 00 00 00 03 B2 01 60
			05 01 00 00 64 00 01 11
                        05 01 00 00 00 00 01 29];	/* display on */
		qcom,mdss-dsi-off-command = [
			05 01 00 00 00 00 01 28		/* display_off */
			05 01 00 00 78 00 01 10];	/* enter sleep mode */

		qcom,mdss-dsi-on-command-state = "dsi_lp_mode";
		qcom,mdss-dsi-off-command-state = "dsi_lp_mode";
		qcom,mdss-dsi-timing-switch-command-state =
			"dsi_lp_mode";
		qcom,compression-mode = "dsc";
		/* Why QCOM doesn't use this, even it used 2 encoder
		 * as for that dsi_sw43404_amoled_cmd, for ex */
		/* qcom,mdss-dsc-encoders = <2>; */
		qcom,mdss-dsc-version = <0x11>;
		qcom,mdss-dsc-slice-height = <12>;
		qcom,mdss-dsc-slice-width = <540>;
		qcom,mdss-dsc-slice-per-pkt = <1>;
		qcom,mdss-dsc-bit-per-component = <10>;
		qcom,mdss-dsc-bit-per-pixel = <8>;
		qcom,mdss-dsc-block-prediction-enable;
		qcom,mdss-dsc-novateck-ic;
	};
};

};

};
